# H3 register map
Vendor: Allwinner; Series: H3; File version: 0.1
CPU: 0, little endian, MPU, no FPU, 0 interrupt priority bits
Registers are 32-bit, read-write, reset 0x0 unless marked. A register's access mark holds for its fields unless they carry their own. Offsets are from the block's base; [hi:lo] are bit positions; lines under a group give offsets from that group; {n}, {i} and the like mark numbered series.

## MSGBOX
Base 0x01C17000
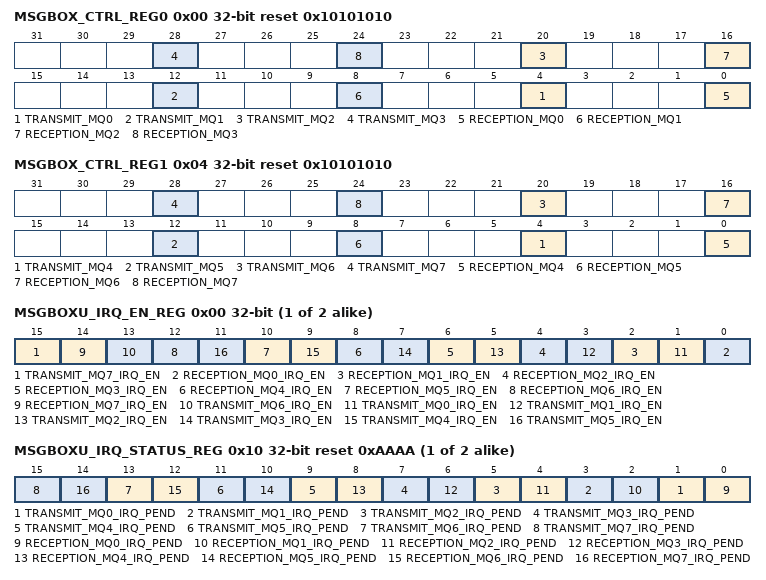
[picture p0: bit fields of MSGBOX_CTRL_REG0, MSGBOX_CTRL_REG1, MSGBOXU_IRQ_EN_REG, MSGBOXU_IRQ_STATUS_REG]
0x00 MSGBOX_CTRL_REG0 reset 0x10101010 — Message Queue Attribute Control Register 0
  [all] fields
    0=user0; 1=user1
  [8n+4] TRANSMIT_MQ{n} (n=0..3) — Message Queue {n} is a Transmitter of user u. 0: user0 1: user1
  [8n] RECEPTION_MQ{n} (n=0..3) — Message Queue {n} is a Receiver of user u. 0: user0 1: user1
0x04 MSGBOX_CTRL_REG1 reset 0x10101010 — Message Queue Attribute Control Register 1
  [all] fields
    0=user0; 1=user1
  [8n-28] TRANSMIT_MQ{n} (n=4..7) — Message Queue {n} is a Transmitter of user u. 0: user0 1: user1
  [8n-32] RECEPTION_MQ{n} (n=4..7) — Message Queue {n} is a Receiver of user u. 0: user0 1: user1
{0x40+0x20*i} _N[{i}] (i=0..1) group
  0x00 MSGBOXU_IRQ_EN_REG — IRQ Enable For User N(N=0,1)
    [15] TRANSMIT_MQ7_IRQ_EN — 0: Disable 1: Enable (It will notify user u by interrupt when Message Queue 7 is not full.)
      0=Disable; 1=Enable (It will notify user u by interrupt when Message Queue 7 is not full.)
    [2n] RECEPTION_MQ{n}_IRQ_EN (n=0..7) — 0: Disable 1: Enable (It will notify user u by interrupt when Message Queue {n} has received a new message.)
      0=Disable; 1=Enable (It will notify user u by interrupt when Message Queue {n} has received a new message.)
    [13] TRANSMIT_MQ6_IRQ_EN — 0: Disable 1: Enable (It will Notify user u by interrupt when Message Queue 6 is not full.)
      0=Disable; 1=Enable (It will Notify user u by interrupt when Message Queue 6 is not full.)
    [2n+1] TRANSMIT_MQ{n}_IRQ_EN (n=0..5) — 0: Disable 1: Enable (It will notify user u by interrupt when Message Queue {n} is not full.)
      0=Disable; 1=Enable (It will notify user u by interrupt when Message Queue {n} is not full.)
  0x10 MSGBOXU_IRQ_STATUS_REG reset 0xAAAA — IRQ Status For User N(N=0,1)
    [2n+1] TRANSMIT_MQ{n}_IRQ_PEND (n=0..7) — 0: No effect, 1: Pending. This bit will be pending for user u when Message Queue {n} is not full. Set one to this bit will clear it.
      0=No_effect; 1=Pending. This bit will be pending for user u when Message Queue {n} is not full. Set one to this bit will clear it.
    [2n] RECEPTION_MQ{n}_IRQ_PEND (n=0..7) — 0: No effect, 1: Pending. This bit will be pending for user u when Message Queue {n} has received a new message. Set one to this bit will clear it.
      0=No_effect; 1=Pending. This bit will be pending for user u when Message Queue {n} has received a new message. Set one to this bit will clear it.
{0x100+4i} _N[{i}] (i=0..7) group
  0x00 MSGBOXM_FIFO_STATUS_REG — FIFO Status For Message Queue N(N = 0~7)
    [0] FIFO_FULL_FLAG ro — 0: The Message FIFO queue is not full (space is available), 1: The Message FIFO queue is full. This FIFO status register has the status related to the message queue.
      0=not_full (The Message FIFO queue is not full (space is available),); 1=full (The Message FIFO queue is full. This FIFO status register has the status related to the message queue.)
  0x40 MSGBOXM_MSG_STATUS_REG — Message Status For Message Queue N(N=0~7)
    [2:0] MSG_NUM ro — Number of unread messages in the message queue. Here, limited to four messages per message queue. 000: There is no message in the message FIFO queue. 001: There is 1 message in the message FIFO queue. 010: There are 2 messages in the message FIFO queue. 011: There are 3 messages in the message FIFO queue. 100: There are 4 messages in the message FIFO queue. 101~111:/
      0=no_message (There is no message in the message FIFO queue.); 1=There is 1 message in the message FIFO queue; 2=There are 2 messages in the message FIFO queue; 3=There are 3 messages in the message FIFO queue; 4=There are 4 messages in the message FIFO queue. 101~111:/
  0x80 MSGBOXM_MSG_REG — Message Register For Message Queue N(N=0~7)
    [31:0] MESSAGE — The message register stores the next to be read message of the message FIFO queue. Reads remove the message from the FIFO queue.
